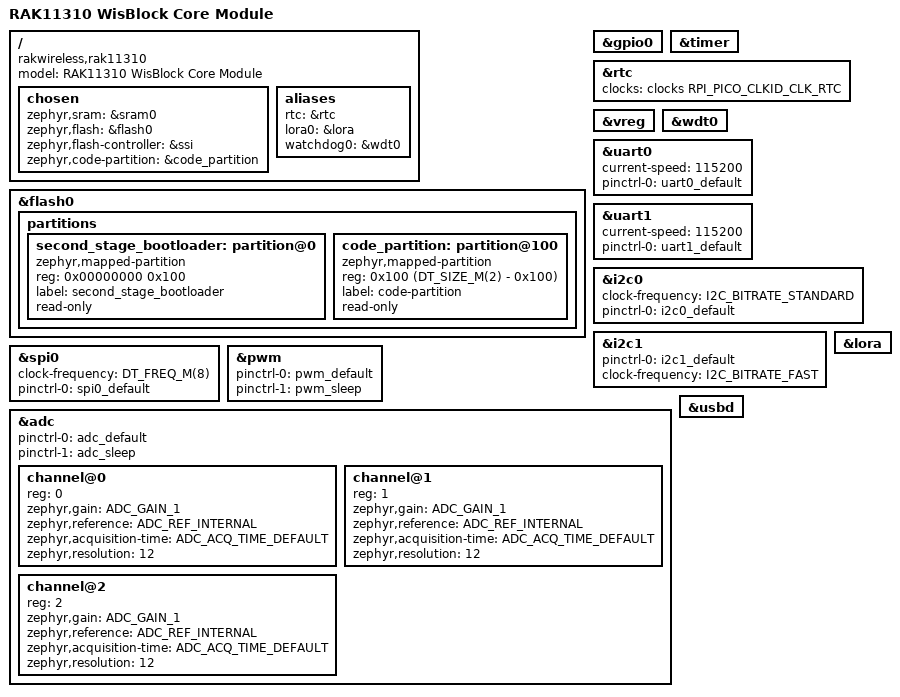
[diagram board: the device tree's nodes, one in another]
/*
 * SPDX-FileCopyrightText: Copyright (c) 2026 RAKwireless Technology Limited
 * SPDX-License-Identifier: Apache-2.0
 */

/dts-v1/;
#include <rakwireless/rak11300.dtsi>
#include "rak11310-pinctrl.dtsi"

/ {
	compatible = "rakwireless,rak11310";
	model = "RAK11310 WisBlock Core Module";

	chosen {
		zephyr,sram = &sram0;
		zephyr,flash = &flash0;
		zephyr,flash-controller = &ssi;
		zephyr,code-partition = &code_partition;
	};

	aliases {
		rtc = &rtc;
		lora0 = &lora;
		watchdog0 = &wdt0;
	};
};

&flash0 {
	partitions {
		ranges;
		#address-cells = <1>;
		#size-cells = <1>;

		/* The boot ROM loads the second stage bootloader from here. */
		second_stage_bootloader: partition@0 {
			compatible = "zephyr,mapped-partition";
			reg = <0x00000000 0x100>;
			label = "second_stage_bootloader";
			read-only;
		};

		code_partition: partition@100 {
			compatible = "zephyr,mapped-partition";
			reg = <0x100 (DT_SIZE_M(2) - 0x100)>;
			label = "code-partition";
			read-only;
		};
	};
};

&gpio0 {
	status = "okay";
};

&timer {
	status = "okay";
};

&rtc {
	clocks = <&clocks RPI_PICO_CLKID_CLK_RTC>;
	status = "okay";
};

&vreg {
	status = "okay";
};

&wdt0 {
	status = "okay";
};

&uart0 {
	current-speed = <115200>;
	pinctrl-0 = <&uart0_default>;
	pinctrl-names = "default";
};

&uart1 {
	current-speed = <115200>;
	pinctrl-0 = <&uart1_default>;
	pinctrl-names = "default";
};

&i2c0 {
	clock-frequency = <I2C_BITRATE_STANDARD>;
	pinctrl-0 = <&i2c0_default>;
	pinctrl-names = "default";
};

&i2c1 {
	pinctrl-0 = <&i2c1_default>;
	pinctrl-names = "default";
	clock-frequency = <I2C_BITRATE_FAST>;
};

&spi0 {
	clock-frequency = <DT_FREQ_M(8)>;
	pinctrl-0 = <&spi0_default>;
	pinctrl-names = "default";
};

&pwm {
	pinctrl-0 = <&pwm_default>;
	pinctrl-1 = <&pwm_sleep>;
	pinctrl-names = "default", "sleep";
	status = "okay";
};

&adc {
	pinctrl-0 = <&adc_default>;
	pinctrl-1 = <&adc_sleep>;
	pinctrl-names = "default", "sleep";
	#address-cells = <1>;
	#size-cells = <0>;
	status = "okay";

	channel@0 {
		reg = <0>;
		zephyr,gain = "ADC_GAIN_1";
		zephyr,reference = "ADC_REF_INTERNAL";
		zephyr,acquisition-time = <ADC_ACQ_TIME_DEFAULT>;
		zephyr,resolution = <12>;
	};

	channel@1 {
		reg = <1>;
		zephyr,gain = "ADC_GAIN_1";
		zephyr,reference = "ADC_REF_INTERNAL";
		zephyr,acquisition-time = <ADC_ACQ_TIME_DEFAULT>;
		zephyr,resolution = <12>;
	};

	channel@2 {
		reg = <2>;
		zephyr,gain = "ADC_GAIN_1";
		zephyr,reference = "ADC_REF_INTERNAL";
		zephyr,acquisition-time = <ADC_ACQ_TIME_DEFAULT>;
		zephyr,resolution = <12>;
	};
};

zephyr_udc0: &usbd {
	status = "okay";
};

#include <../boards/common/usb/cdc_acm_serial.dtsi>

&lora {
	status = "okay";
};

#include "wisblock.dtsi"
